VERSION ""

NS_ :

BS_:

BU_:

BO_ 1600 M1_General_0x640: 8 Vector__XXX
 SG_ Throttle_Position : 55|16@0+ (0.1,0) [0|100] "%" Vector__XXX
 SG_ Engine_Speed : 7|16@0+ (1,0) [0|16000] "RPM" Vector__XXX

BO_ 1614 M1_General_0x64E: 8 Vector__XXX
 SG_ Brake_Switch : 27|1@0+ (1,0) [0|1] "" Vector__XXX

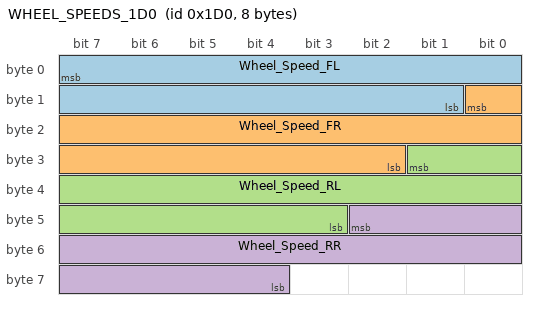
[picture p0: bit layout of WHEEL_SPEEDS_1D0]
BO_ 464 WHEEL_SPEEDS_1D0: 8 Vector__XXX
 SG_ Wheel_Speed_FL : 7|15@0+ (0.01,0) [0|250] "kph" Vector__XXX
 SG_ Wheel_Speed_FR : 8|15@0+ (0.01,0) [0|250] "kph" Vector__XXX
 SG_ Wheel_Speed_RL : 25|15@0+ (0.01,0) [0|250] "kph" Vector__XXX
 SG_ Wheel_Speed_RR : 42|15@0+ (0.01,0) [0|250] "kph" Vector__XXX
